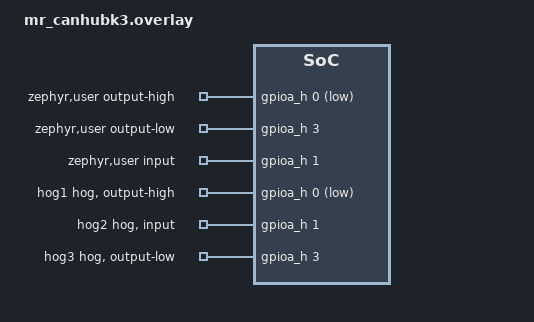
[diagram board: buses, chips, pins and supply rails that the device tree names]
/*
 * Copyright 2023 NXP
 *
 * SPDX-License-Identifier: Apache-2.0
 */

#include <zephyr/dt-bindings/gpio/gpio.h>

/ {
	zephyr,user {
		output-high-gpios = <&gpioa_h 0 GPIO_ACTIVE_LOW>;
		output-low-gpios = <&gpioa_h 3 GPIO_ACTIVE_HIGH>;
		input-gpios = <&gpioa_h 1 GPIO_ACTIVE_HIGH>;
	};
};

&gpioa_h {
	hog1 {
		gpio-hog;
		gpios = <0 GPIO_ACTIVE_LOW>;
		output-high;
	};

	hog2 {
		gpio-hog;
		gpios = <1 GPIO_ACTIVE_HIGH>;
		input;
	};

	hog3 {
		gpio-hog;
		gpios = <3 GPIO_ACTIVE_HIGH>;
		output-low;
	};
};
